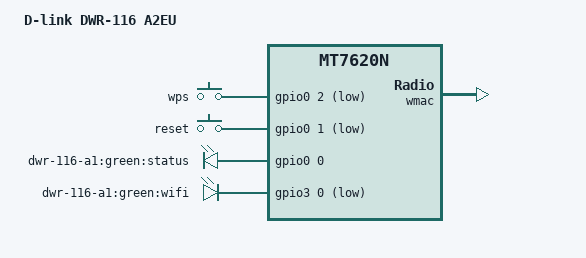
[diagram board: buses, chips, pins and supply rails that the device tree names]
/dts-v1/;

#include "DWR-116-A.dtsi"

/ {
	compatible = "dlink,dwr-116-a2eu", "ralink,mt7620n-soc";
	model = "D-link DWR-116 A2EU";

	gpio-keys-polled {
		compatible = "gpio-keys-polled";
		#address-cells = <1>;
		#size-cells = <0>;
		poll-interval = <20>;

		wps {
			label = "wps";
			gpios = <&gpio0 2 GPIO_ACTIVE_LOW>;
			linux,code = <KEY_WPS_BUTTON>;
		};
		reset {
			label = "reset";
			gpios = <&gpio0 1 GPIO_ACTIVE_LOW>;
			linux,code = <KEY_RESTART>;
		};
	};

	gpio-leds {
		compatible = "gpio-leds";

		status {
			label = "dwr-116-a1:green:status";
			gpios = <&gpio0 0 GPIO_ACTIVE_HIGH>;
		};
		wifi {
			label = "dwr-116-a1:green:wifi";
			gpios = <&gpio3 0 GPIO_ACTIVE_LOW>;
		};
	};

};

&ethernet {
	mtd-mac-address = <&config 0xe2a2>;
	mediatek,portmap = "llllw";
	pinctrl-names = "default";
	pinctrl-0 = <&ephy_pins>;
};

&wmac {
	ralink,mtd-eeprom = <&config 0xe095>;
};


